# NUC100DN_v1 register map
File version: 1.0
Registers are 32-bit, read-write, reset 0x0 unless marked. A register's access mark holds for its fields unless they carry their own. Offsets are from the block's base; [hi:lo] are bit positions; {n}, {i} and the like mark numbered series.

## GCR — GCR Register Map
Base 0x50000000
0x00 PDID ro reset 0x20140018 — Part Device Identification Number Register
  [31:0] PDID — Part Device Identification Number. This register reflects device part number code. Software can read this register to identify which device is used.
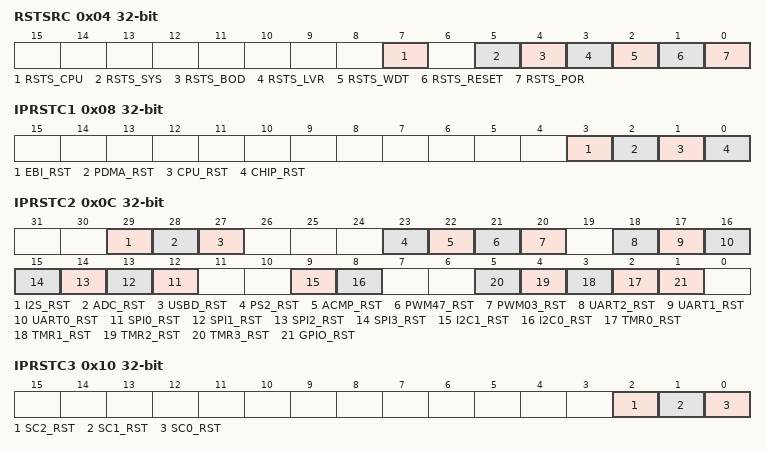
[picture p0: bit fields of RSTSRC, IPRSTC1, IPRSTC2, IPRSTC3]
0x04 RSTSRC (reset mask 0xFFFFFF00) — System Reset Source Register
  [7] RSTS_CPU — CPU Reset Flag. The RSTS_CPU flag is set by hardware if software writes cpu_rst (iprstc1[1]) 1 to reset Cortex-M0 cpu core and flash memory controller (fmc). Note: This bit can be cleared by writing '1' to it.
    0=No reset from CPU; 1=Cortex-M0 CPU core and FMC are reset by software setting CPU_RST to 1
  [5] RSTS_SYS — SYS Reset Flag. The RSTS_SYS flag is set by the "reset signal" from the Cortex-M0 core to indicate the previous reset source. Note: This bit can be cleared by writing '1' to it.
    0=No reset from Cortex-M0; 1=The Cortex-M0 had issued the reset signal to reset the system by writing 1 to bit SYSRESETREQ (AIRCR[2], Application Interrupt and Reset Control Register, address = 0xE000ED0C) in system control registers of Cortex-M0 core
  [4] RSTS_BOD — Brown-out Detector Reset Flag. The RSTS_BOD flag is set by the "reset signal" from the brown-out detector to indicate the previous reset source. Note: This bit can be cleared by writing '1' to it.
    0=No reset from BOD; 1=The BOD had issued the reset signal to reset the system
  [3] RSTS_LVR — Low Voltage Reset Flag. The RSTS_LVR flag is set by the "reset signal" from fhe low-voltage-reset controller fo indicate the previous reset source. Note: This bit can be cleared by writing '1' to it.
    0=No reset from LVR; 1=The LVR controller had issued the reset signal to reset the system
  [2] RSTS_WDT — Watchdog Timer Reset Flag. The RSTS_WDT flag is set by the "reset signal" from the watchdog timer to indicate the previous reset source. Note: This bit can be cleared by writing '1' to it.
    0=No reset from watchdog timer; 1=The watchdog timer had issued the reset signal to reset the system
  [1] RSTS_RESET — Reset Pin Reset Flag. The RSTS_RESET flag is set by the "reset signal" from the /reset pin to indicate the previous reset source. Note: This bit can be cleared by writing '1' to it.
    0=No reset from /RESET pin; 1=The Pin /RESET had issued the reset signal to reset the system
  [0] RSTS_POR — Power-on Reset Flag. The RSTS_POR flag is Set by the "Reset Signal" from the Power-on Reset (POR) controller or the bit CHIP_RST (IPRSTC1[0]) to indicate the previous reset source. Note: This bit can be cleared by writing '1' to it.
    0=No reset from POR or CHIP_RST; 1=Power-on Reset (POR) or CHIP_RST had issued the reset signal to reset the system
0x08 IPRSTC1 — IP Reset Control Register 1
  [3] EBI_RST — EBI Controller Reset (Write Protect). Set this bit to 1 will generate a reset signal to the EBI. User need to set this bit to 0 to release from the reset state. This bit is the protected bit, It means programming this bit needs to write "59h", "16h", "88h" to address 0x5000_0100 to disable register protection. Refer to the register REGWRPROT at address GCR_BA+0x100
    0=EBI controller normal operation; 1=EBI controller reset
  [2] PDMA_RST — PDMA Controller Reset (Write Protect). Setting this bit to 1 will generate a reset signal to the PDMA. User need to set this bit to 0 to release from reset state. This bit is the protected bit, It means programming this bit needs to write "59h", "16h", "88h" to address 0x5000_0100 to disable register protection. Refer to the register REGWRPROT at address GCR_BA+0x100.
    0=PDMA controller normal operation; 1=PDMA controller reset
  [1] CPU_RST — CPU Core One-shot Reset (Write Protect). Setting this bit will only reset the CPU core and Flash Memory Controller(FMC), and this bit will automatically return 0 after the two clock cycles. This bit is the protected bit, It means programming this bit needs to write "59h", "16h", "88h" to address 0x5000_0100 to disable register protection. Refer to the register REGWRPROT at address GCR_BA+0x100
    0=CPU normal operation; 1=CPU one-shot reset
  [0] CHIP_RST — CHIP One-shot Reset (Write Protect). Setting this bit will reset the whole chip, including CPU core and all peripherals, and this bit will automatically return to 0 after the 2 clock cycles. The CHIP_RST is the same as the POR reset, all the chip controllers are reset and the chip setting from flash are also reload. For the difference between CHIP_RST and SYSRESETREQ, please refer to section 5.2.2. This bit is the protected bit. It means programming this bit needs to write "59h", "16h", "88h" to address 0x5000_0100 to disable register protection. Refer to the register REGWRPROT at address GCR_BA+0x100
    0=CHIP normal operation; 1=CHIP one-shot reset
0x0C IPRSTC2 — IP Reset Control Register 2
  [29] I2S_RST — I2S Controller Reset
    0=I2S controller normal operation; 1=I2S controller reset
  [28] ADC_RST — ADC Controller Reset
    0=ADC controller normal operation; 1=ADC controller reset
  [27] USBD_RST — USB Device Controller Reset
    0=USB device controller normal operation; 1=USB device controller reset
  [23] PS2_RST — PS/2 Controller Reset
    0=PS/2 controller normal operation; 1=PS/2 controller reset
  [22] ACMP_RST — Analog Comparator Controller Reset
    0=Analog Comparator controller normal operation; 1=Analog Comparator controller reset
  [21] PWM47_RST — PWM47 Controller Reset
    0=PWM47 controller normal operation; 1=PWM47 controller reset
  [20] PWM03_RST — PWM03 Controller Reset
    0=PWM03 controller normal operation; 1=PWM03 controller reset
  [18] UART2_RST — UART2 Controller Reset
    0=UART2 controller normal operation; 1=UART2 controller reset
  [17] UART1_RST — UART1 Controller Reset
    0=UART1 controller normal operation; 1=UART1 controller reset
  [16] UART0_RST — UART0 Controller Reset
    0=UART0 controller normal operation; 1=UART0 controller reset
  [n+12] SPI{n}_RST (n=0..3) — SPI{n} Controller Reset
    0=SPI{n} controller normal operation; 1=SPI{n} controller reset
  [9] I2C1_RST — I2C1 Controller Reset
    0=I2C1 controller normal operation; 1=I2C1 controller reset
  [8] I2C0_RST — I2C0 Controller Reset
    0=I2C0 controller normal operation; 1=I2C0 controller reset
  [n+2] TMR{n}_RST (n=0..3) — Timer{n} Controller Reset
    0=Timer{n} controller normal operation; 1=Timer{n} controller reset
  [1] GPIO_RST — GPIO Controller Reset
    0=GPIO controller normal operation; 1=GPIO controller reset
0x10 IPRSTC3 — IP Reset Control Register 3
  [2] SC2_RST — SC2 Controller Reset
    0=SC2 controller normal operation; 1=SC2 controller reset
  [1] SC1_RST — SC1 Controller Reset
    0=SC1 controller normal operation; 1=SC1 controller reset
  [0] SC0_RST — SC0 Controller Reset
    0=SC0 controller normal operation; 1=SC0 controller reset
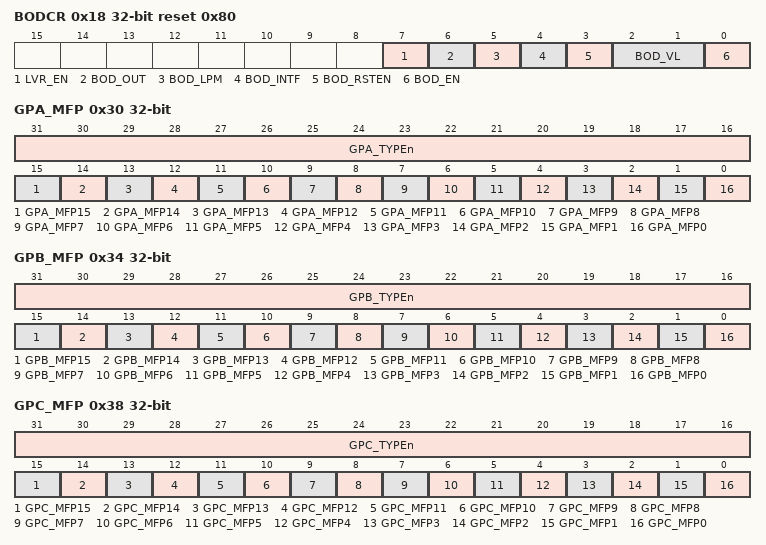
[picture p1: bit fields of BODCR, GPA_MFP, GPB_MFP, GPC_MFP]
0x18 BODCR reset 0x80 (reset mask 0xFFFFFFF0) — Brown-out Detector Control Register
  [7] LVR_EN — Low Voltage Reset Enable Bit (Write Protect). The LVR function reset the chip when the input power voltage is lower than LVR circuit setting. LVR function is enabled by default. This bit is the protected bit. It means programming this needs to write "59h", "16h", "88h" to address 0x5000_0100 to disable register protection. Refer to the register REGWRPROT at address GCR_BA+0x100
    0=Low Voltage Reset function Disabled; 1=Low Voltage Reset function Enabled - After enabling the bit, the LVR function will be active with 100us delay for LVR output stable (default)
  [6] BOD_OUT — Brown-out Detector Output Status
    0=Brown-out Detector output status is 0. It means the detected voltage is higher than BOD_VL setting or BOD_EN is 0; 1=Brown-out Detector output status is 1. It means the detected voltage is lower than BOD_VL setting. If the BOD_EN is 0, BOD function disabled , this bit always responds to 0
  [5] BOD_LPM — Brown-out Detector Low Power Mode (Write Protect). The BOD consumes about 100 uA in Normal mode, and the low power mode can reduce the current to about 1/10 but slow the BOD response. This bit is the protected bit which means programming this needs to write "59h", "16h", "88h" to address 0x5000_0100 to disable register protection. Refer to the register REGWRPROT at address GCR_BA+0x100.
    0=BOD operated in Normal mode (default); 1=BOD Low Power mode Enabled
  [4] BOD_INTF — Brown-out Detector Interrupt Flag. Note: This bit can be cleared by writing '1' to it.
    0=Brown-out Detector does not detect any voltage draft at VDD down through or up through the voltage of BOD_VL setting; 1=When Brown-out Detector detects the VDD is dropped down through the voltage of BOD_VL setting or the VDD is raised up through the voltage of BOD_VL setting, this bit is set to 1 and the Brown-out interrupt is requested if Brown-out interrupt is enabled
  [3] BOD_RSTEN — Brown-out Reset Enable Bit (Write Protect). While the Brown-out Detector function is enabled (BOD_EN high) and BOD reset function is enabled (BOD_RSTEN high), BOD will assert a signal to reset chip when the detected voltage is lower than the threshold (BOD_OUT high). The default value is set by flash controller user configuration register config0 bit[20]. This bit is the protected bit. It means programming this needs to write "59h", "16h", "88h" to address 0x5000_0100 to disable register protection. Refer to the register REGWRPROT at address GCR_BA+0x100.
    0=Brown-out "INTERRUPT" function Enabled; 1=Brown-out "RESET" function Enabled
  [2:1] BOD_VL — Brown-out Detector Threshold Voltage Selection (Write Protect)
  [0] BOD_EN — Brown-out Detector Enable Bit (Write Protect). The default value is set by flash controller user configuration register config0 bit[23]. This bit is the protected bit which means programming this needs to write "59h", "16h", "88h" to address 0x5000_0100 to disable register protection. Refer to the register REGWRPROT at address GCR_BA+0x100.
    0=Brown-out Detector function Disabled; 1=Brown-out Detector function Enabled
0x1C TEMPCR — Temperature Sensor Control Register
  [0] VTEMP_EN — Temperature Sensor Enable Bit. This bit is used to enable/disable temperature sensor function. After this bit is set to 1, the value of temperature can be obtained from ADC conversion result by ADC channel selecting channel 7 and alternative multiplexer channel selecting temperature sensor. Please refer to the ADC function chapter for detail ADC conversion functional description.
    0=Temperature sensor function Disabled (default); 1=Temperature sensor function Enabled
0x24 PORCR (reset mask 0xFFFFFF00) — Power-on-reset Controller Register
  [15:0] POR_DIS_CODE — Power-on-reset Enable Control (Write Protect). When powered on, the POR circuit generates a reset signal to reset the whole chip function, but noise on the power may cause the POR active again. User can disable internal POR circuit to avoid unpredictable noise to cause chip reset by writing 0x5AA5 to this field. The POR function will be active again when this field is set to another value or chip is reset by other reset source, including: /RESET, Watchdog, LVR reset, BOD reset, ICE reset command and the software-chip reset function. This bit is the protected bit which means programming this needs to write "59h", "16h", "88h" to address 0x5000_0100 to disable register protection. Refer to the register REGWRPROT at address GCR_BA+0x100.
0x30 GPA_MFP — GPIOA Multiple Function and Input Type Control Register
  [31:16] GPA_TYPEn — Input Schmitt Trigger Enable Bit
    0=GPIOA[15:0] I/O input Schmitt Trigger function Disabled; 1=GPIOA[15:0] I/O input Schmitt Trigger function Enabled
  [15] GPA_MFP15 — PA.15 Pin Function Selection
  [14] GPA_MFP14 — PA.14 Pin Function Selection
  [13] GPA_MFP13 — PA.13 Pin Function Selection
  [12] GPA_MFP12 — PA.12 Pin Function Selection
  [11] GPA_MFP11 — PA.11 Pin Function Selection
  [10] GPA_MFP10 — PA.10 Pin Function Selection
  [9] GPA_MFP9 — PA.9 Pin Function Selection
    0=GPIOA[9] selected to the pin PA.9; 1=I2C0 SCL function selected to the pin PA.9
  [8] GPA_MFP8 — PA.8 Pin Function Selection
    0=GPIOA[8] selected to the pin PA.8; 1=I2C0 SDA function selected to the pin PA.8
  [7] GPA_MFP7 — PA.7 Pin Function Selection
  [6] GPA_MFP6 — PA.6 Pin Function Selection
  [5] GPA_MFP5 — PA.5 Pin Function Selection
  [4] GPA_MFP4 — PA.4 Pin Function Selection
  [3] GPA_MFP3 — PA.3 Pin Function Selection
  [2] GPA_MFP2 — PA.2 Pin Function Selection
  [1] GPA_MFP1 — PA.1 Pin Function Selection
  [0] GPA_MFP0 — PA.0 Pin Function Selection
0x34 GPB_MFP — GPIOB Multiple Function and Input Type Control Register
  [31:16] GPB_TYPEn — Input Schmitt Trigger Enable Bit
    0=GPIOB[15:0] I/O input Schmitt Trigger function Disabled; 1=GPIOB[15:0] I/O input Schmitt Trigger function Enabled
  [15] GPB_MFP15 — PB.15 Pin Function Selection
  [14] GPB_MFP14 — PB.14 Pin Function Selection
  [13] GPB_MFP13 — PB.13 Pin Function Selection
  [12] GPB_MFP12 — PB.12 Pin Function Selection
  [11] GPB_MFP11 — PB.11 Pin Function Selection
  [10] GPB_MFP10 — PB.10 Pin Function Selection
  [9] GPB_MFP9 — PB.9 Pin Function Selection
  [8] GPB_MFP8 — PB.8 Pin Function Selection
    0=GPIOB[8] selected to the pin PB.8; 1=TM0 (Timer/Counter external trigger clock input) function selected to the pin PB.8
  [7] GPB_MFP7 — PB.7 Pin Function Selection
  [6] GPB_MFP6 — PB.6 Pin Function Selection
  [5] GPB_MFP5 — PB 5 Pin Function Selection
    0=GPIOB[5] is selected to the pin PB.5; 1=UART1 TXD function is selected to the pin PB.5
  [4] GPB_MFP4 — PB.4 Pin Function Selection
    0=GPIOB[4] is selected to the pin PB.4; 1=UART1 RXD function is selected to the pin PB.4
  [3] GPB_MFP3 — PB.3 Pin Function Selection
  [2] GPB_MFP2 — PB.2 Pin Function Selection
  [1] GPB_MFP1 — PB.1 Pin Function Selection
    0=GPIOB[1] is selected to the pin PB.1; 1=UART0 TXD function is selected to the pin PB.1
  [0] GPB_MFP0 — PB.0 Pin Function Selection
    0=GPIOB[0] is selected to the pin PB.0; 1=UART0 RXD function is selected to the pin PB.0
0x38 GPC_MFP — GPIOC Multiple Function and Input Type Control Register
  [31:16] GPC_TYPEn — Input Schmitt Trigger Enable Bit
    0=GPIOC[15:0] I/O input Schmitt Trigger function Disabled; 1=GPIOC[15:0] I/O input Schmitt Trigger function Enabled
  [15] GPC_MFP15 — PC.15 Pin Function Selection
  [14] GPC_MFP14 — PC.14 Pin Function Selection
  [13] GPC_MFP13 — PC.13 Pin Function Selection
    0=GPIOC[13] is selected to the pin PC.13; 1=SPI1 MOSI1 (master output, slave input pin-1) function is selected to the pin PC.13
  [12] GPC_MFP12 — PC.12 Pin Function Selection
    0=GPIOC[12] is selected to the pin PC.12; 1=SPI1 MISO1 (master input, slave output pin-1) function is selected to the pin PC.12
  [11] GPC_MFP11 — PC.11 Pin Function Selection
    0=GPIOC[11] selected to the pin PC.11; 1=SPI1 MOSI0 (master output, slave input pin-0) function selected to the pin PC.11
  [10] GPC_MFP10 — PC.10 Pin Function Selection
    0=GPIOC[10] is selected to the pin PC.10; 1=SPI1 MISO0 (master input, slave output pin-0) function selected to the pin PC.10
  [9] GPC_MFP9 — PC.9 Pin Function Selection
    0=GPIOC[9] selected to the pin PC.9; 1=SPI1 SPICLK function selected to the pin PC.9
  [8] GPC_MFP8 — PC.8 Pin Function Selection
  [7] GPC_MFP7 — PC.7 Pin Function Selection
  [6] GPC_MFP6 — PC.6 Pin Function Selection
  [5] GPC_MFP5 — PC.5 Pin Function Selection
    0=GPIOC[5] is selected to the pin PC.5; 1=SPI0 MOSI1 (master output, slave input pin-1) function is selected to the pin PC.5
  [4] GPC_MFP4 — PC.4 Pin Function Selection
    0=GPIOC[4] is selected to the pin PC.4; 1=SPI0 MISO1 (master input, slave output pin-1) function is selected to the pin PC.4
  [3] GPC_MFP3 — PC.3 Pin Function Selection
  [2] GPC_MFP2 — PC.2 Pin Function Selection
  [1] GPC_MFP1 — PC.1 Pin Function Selection
  [0] GPC_MFP0 — PC.0 Pin Function Selection
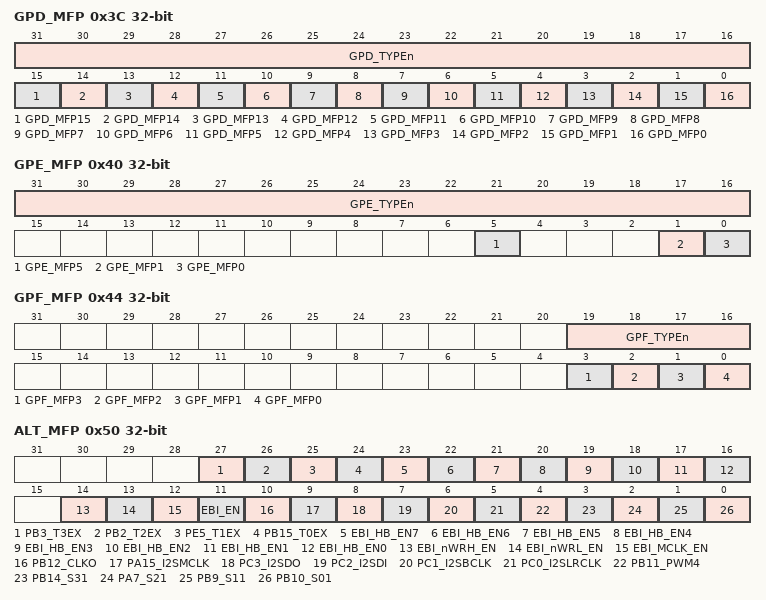
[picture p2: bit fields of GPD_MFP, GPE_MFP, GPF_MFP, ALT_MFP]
0x3C GPD_MFP — GPIOD Multiple Function and Input Type Control Register
  [31:16] GPD_TYPEn — Input Schmitt Trigger Enable Bit
    0=GPIOD[15:0] I/O input Schmitt Trigger function Disabled; 1=GPIOD[15:0] I/O input Schmitt Trigger function Enabled
  [15] GPD_MFP15 — PD.15 Pin Function Selection
    0=GPIOD[15] selected to the pin PD.15; 1=UART2 TXD function is selected to the pin PD.15
  [14] GPD_MFP14 — PD.14 Pin Function Selection
    0=GPIOD[14] selected to the pin PD.14; 1=UART2 RXD function is selected to the pin PD.14
  [13] GPD_MFP13 — PD.13 Pin Function Selection
    0=GPIOD[13] is selected to the pin PD.13; 1=SPI3 MOSI1 (master output, slave input pin-1) function is selected to the pin PD.13
  [12] GPD_MFP12 — PD.12 Pin Function Selection
    0=GPIOD[12] is selected to the pin PD.12; 1=SPI3 MISO1 (master input, slave output pin-1) function is selected to the pin PD.12
  [11] GPD_MFP11 — PD.11 Pin Function Selection
    0=GPIOD[11] is selected to the pin PD.11; 1=SPI3 MOSI0 (master output, slave input pin-0) function is selected to the pin PD.11
  [10] GPD_MFP10 — PD.10 Pin Function Selection
    0=GPIOD[10] is selected to the pin PD.10; 1=SPI3 MISO0 (master input, slave output pin-0) function is selected to the pin PD.10
  [9] GPD_MFP9 — PD.9 Pin Function Selection
    0=GPIOD[9] is selected to the pin PD.9; 1=SPI3 SPICLK function is selected to the pin PD.9
  [8] GPD_MFP8 — PD.8 Pin Function Selection
    0=GPIOD[8] is selected to the pin PD8; 1=SPI3 SS30 function is selected to the pin PD8
  [7] GPD_MFP7 — Reserved.
  [6] GPD_MFP6 — Reserved.
  [5] GPD_MFP5 — PD.5 Pin Function Selection
    0=GPIOD[5] is selected to the pin PD.5; 1=SPI2 MOSI1 (master output, slave input pin-1) function is selected to the pin PD.5
  [4] GPD_MFP4 — PD.4 Pin Function Selection
    0=GPIOD[4]is selected to the pin PD.4; 1=SPI2 MISO1 (master input, slave output pin-1) function is selected to the pin PD.4
  [3] GPD_MFP3 — PD.3 Pin Function Selection
    0=GPIOD[3] selected to the pin PD.3; 1=SPI2 MOSI0 (master output, slave input pin-0) function selected to the pin PD.3
  [2] GPD_MFP2 — PD.2 Pin Function Selection
    0=GPIOD[2] selected to the pin PD.2; 1=SPI2 MISO0 (master input, slave output pin-0) function selected to the pin PD.2
  [1] GPD_MFP1 — PD.1 Pin Function Selection
    0=GPIOD[1] selected to the pin PD.1; 1=SPI2 SPICLK function selected to the pin PD.1
  [0] GPD_MFP0 — PD.0 Pin Function Selection
    0=GPIOD[0] selected to the pin PD.0; 1=SPI2 SS20 function selected to the pin PD.0
0x40 GPE_MFP — GPIOE Multiple Function and Input Type Control Register
  [31:16] GPE_TYPEn — Input Schmitt Trigger Enable Bit
    0=GPIOE[15:0] I/O input Schmitt Trigger function Disabled; 1=GPIOE[15:0] I/O input Schmitt Trigger function Enabled
  [5] GPE_MFP5 — PE.5 Pin Function Selection
  [1] GPE_MFP1 — PE.1 Pin Function Selection
    0=GPIOE[1] is selected to the pin PE.1; 1=PWM7 function is selected to the pin PE.1
  [0] GPE_MFP0 — PE.0 Pin Function Selection
    0=GPIOE[0] is selected to the pin PE.0; 1=PWM6 function is selected to the pin PE.0
0x44 GPF_MFP (reset mask 0xFFFFFFF0) — GPIOF Multiple Function and Input Type Control Register
  [19:16] GPF_TYPEn — Input Schmitt Trigger Enable Bit
    0=GPIOF[3:0] I/O input Schmitt Trigger function Disabled; 1=GPIOF[3:0] I/O input Schmitt Trigger function Enabled
  [3] GPF_MFP3 — PF.3 Pin Function Selection
    0=GPIOF[3] is selected to the pin PF.3; 1=PS2CLK function is selected to the pin PF.3
  [2] GPF_MFP2 — PF.2 Pin Function Selection
    0=GPIOF[2] is selected to the pin PF.2; 1=PS2DAT function is selected to the pin PF.2
  [1] GPF_MFP1 — PF.1 Pin Function Selection. Note: This bit is read only and is decided by user configuration CGPFMFP (Config0[27]).
    0=GPIOF[1] is selected to the pin PF.1; 1=XT1_IN function is selected to the pin PF.1
  [0] GPF_MFP0 — PF.0 Pin Function Selection. Note: This bit is read only and is decided by user configuration CGPFMFP (Config0[27]).
    0=GPIOF[0] is selected to the pin PF.0; 1=XT1_OUT function is selected to the pin PF.0
0x50 ALT_MFP — Alternative Multiple Function Pin Control Register
  [27] PB3_T3EX — PB.3 Pin Function Selection
  [26] PB2_T2EX — PB.2 Pin Function Selection
  [25] PE5_T1EX — PE.5 Pin Function Selection
  [24] PB15_T0EX — PB.15 Pin Function Selection
  [23] EBI_HB_EN7 — PA.14 Pin Function Selection
  [22] EBI_HB_EN6 — PA.13 Pin Function Selection
  [21] EBI_HB_EN5 — PA.12 Pin Function Selection
  [20] EBI_HB_EN4 — PA.1 Pin Function Selection
  [19] EBI_HB_EN3 — PA.2 Pin Function Selection
  [18] EBI_HB_EN2 — PA.3 Pin Function Selection
  [17] EBI_HB_EN1 — PA.4 Pin Function Selection
  [16] EBI_HB_EN0 — PA.5 Pin Function Selection
  [14] EBI_nWRH_EN — PB.3 Pin Function Selection
  [13] EBI_nWRL_EN — PB.2 Pin Function Selection
  [12] EBI_MCLK_EN — PC.8 Pin Function Selection
  [11] EBI_EN — EBI Function Selection
  [10] PB12_CLKO — PB.12 Pin Function Selection
  [9] PA15_I2SMCLK — PA.15 Pin Function Selection
  [8] PC3_I2SDO — PC.3 Pin Function Selection
  [7] PC2_I2SDI — PC.2 Pin Function Selection
  [6] PC1_I2SBCLK — PC.1 Pin Function Selection
  [5] PC0_I2SLRCLK — PC.0 Pin Function Selection
  [4] PB11_PWM4 — PB.11 Pin Function Selection
  [3] PB14_S31 — PB.14 Pin Function Selection
  [2] PA7_S21 — PA.7 Pin Function Selection
  [1] PB9_S11 — PB.9 Pin Function Selection
  [0] PB10_S01 — PB.10 Pin Function Selection
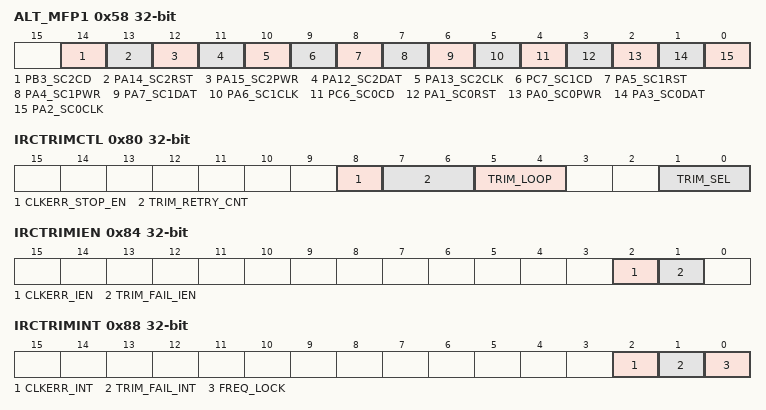
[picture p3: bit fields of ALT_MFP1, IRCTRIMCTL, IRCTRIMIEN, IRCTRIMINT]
0x58 ALT_MFP1 — Alternative Multiple Function Pin Control Register 1
  [14] PB3_SC2CD — PB.3 Pin Function Selection
  [13] PA14_SC2RST — PA.14 Pin Function Selection
  [12] PA15_SC2PWR — PA.15 Pin Function Selection
  [11] PA12_SC2DAT — PA.12 Pin Function Selection
  [10] PA13_SC2CLK — PA.13 Pin Function Selection
  [9] PC7_SC1CD — PC.7 Pin Function Selection
  [8] PA5_SC1RST — PA.5 Pin Function Selection
  [7] PA4_SC1PWR — PA.4 Pin Function Selection
  [6] PA7_SC1DAT — PA.7 Pin Function Selection
  [5] PA6_SC1CLK — PA.6 Pin Function Selection
  [4] PC6_SC0CD — PC.6 Pin Function Selection
  [3] PA1_SC0RST — PA.1 Pin Function Selection
  [2] PA0_SC0PWR — PA.0 Pin Function Selection
  [1] PA3_SC0DAT — PA.3 Pin Function Selection
  [0] PA2_SC0CLK — PA.2 Pin Function Selection
0x80 IRCTRIMCTL — IRC Trim Control Register
  [8] CLKERR_STOP_EN — Clock Error Stop Enable Bit. When this bit is set to 1, the trim operation is stopped if clock is inaccuracy. When this bit is set to 0, the trim operation is keep going if clock is inaccuracy.
  [7:6] TRIM_RETRY_CNT — Trim Value Update Limitation Count. The field defines that how many times of HIRC trim value is updated by auto trim circuit before the HIRC frequency locked. Once the HIRC locked, the internal trim value update counter will be reset. If the trim value update counter reached this limitation value and frequency of HIRC still doesn't lock, the auto trim operation will be disabled and TRIM_SEL will be cleared to 00.
    0=Trim retry count limitation is 64; 1=Trim retry count limitation is 128; 2=Trim retry count limitation is 256; 3=Trim retry count limitation is 512
  [5:4] TRIM_LOOP — Trim Calculation Loop. This field defines that trim value calculation is based on how many 32.768 kHz clocks in. For example, if TRIM_LOOP is set as 00, auto trim circuit will calculate trim value based on the average frequency difference in 4 32.768 kHz clock.
    0=Trim value calculation is based on average difference in 4 clocks; 1=Trim value calculation is based on average difference in 8 clocks; 2=Trim value calculation is based on average difference in 16 clocks; 3=Trim value calculation is based on average difference in 32 clocks
  [1:0] TRIM_SEL — Trim Frequency Selection. This field indicates the target frequency of internal 22.1184 MHz high speed oscillator will trim to precise 22.1184MHz or 24MHz automatically. If no any target frequency is selected (TRIM_SEL is 00), the HIRC auto trim function is disabled. During auto trim operation, if clock error detected because of CLKERR_STOP_EN is set to 1 or trim retry limitation counts reached, this field will be cleared to 00 automatically.
    0=HIRC auto trim function Disabled; 1=HIRC auto trim function Enabled and HIRC trimmed to 22.1184 MHz; 2=HIRC auto trim function Enabled and HIRC trimmed to 24 MHz
0x84 IRCTRIMIEN — IRC Trim Interrupt Enable Register
  [2] CLKERR_IEN — Clock Error Interrupt Enable Bit. This bit controls if CPU would get an interrupt while clock is inaccuracy during auto trim operation. If this bit is set to1, and CLKERR_INT is set during auto trim operation. An interrupt will be triggered to notify the clock frequency is inaccuracy.
    0=CLKERR_INT status to trigger an interrupt to CPU Disabled; 1=CLKERR_INT status to trigger an interrupt to CPU Enabled
  [1] TRIM_FAIL_IEN — Trim Failure Interrupt Enable Bit. This bit controls if an interrupt will be triggered while HIRC trim value update limitation count reached and HIRC frequency still not locked on target frequency set by TRIM_SEL. If this bit is high and TRIM_FAIL_INT is set during auto trim operation. An interrupt will be triggered to notify that HIRC trim value update limitation count was reached.
    0=TRIM_FAIL_INT status to trigger an interrupt to CPU Disabled; 1=TRIM_FAIL_INT status to trigger an interrupt to CPU Enabled
0x88 IRCTRIMINT — IRC Trim Interrupt Status Register
  [2] CLKERR_INT — Clock Error Interrupt Status. When the frequency of external 32.768 kHz low speed crystal or internal 22.1184 MHz high speed oscillator is shift larger to unreasonable value, this bit will be set and to be an indicate that clock frequency is inaccuracy. Once this bit is set to 1, the auto trim operation stopped and TRIM_SEL will be cleared to 00 by hardware automatically if CLKERR_STOP_EN is set to 1. If this bit is set and CLKERR_IEN is high, an interrupt will be triggered to notify the clock frequency is inaccuracy. Write 1 to clear this to 0.
    0=Clock frequency is accurate; 1=Clock frequency is inaccurate
  [1] TRIM_FAIL_INT — Trim Failure Interrupt Status. This bit indicates that internal 22.1184 MHz high speed oscillator trim value update limitation count reached and the internal 22.1184 MHz high speed oscillator clock frequency still doesn't be locked. Once this bit is set, the auto trim operation stopped and TRIM_SEL will be cleared to 00 by hardware automatically. If this bit is set and TRIM_FAIL_IEN is high, an interrupt will be triggered to notify that HIRC trim value update limitation count was reached. Write 1 to clear this to 0.
    0=Trim value update limitation count did not reach; 1=Trim value update limitation count reached and internal 22.1184 MHz high speed oscillator frequency was still not locked
  [0] FREQ_LOCK — HIRC Frequency Lock Status. This bit indicates the internal 22.1184 MHz high speed oscillator frequency is locked. This is a status bit and doesn't trigger any interrupt.
0x100 REGWRPROT — Register Write Protection Register
  [7:0] REGWRPROT — Register Write-protection Code. Some registers have write-protection function. Writing these registers have to disable the protected function by writing the sequence value "59h", "16h", "88h" to this field. After this sequence is completed, the REGPROTDIS bit will be set to 1 and write-protection registers can be normal write. Register Write-protection Disable Index
    0=Write-protection is enabled for writing protected registers. Any write to the protected register is ignored; 1=Write-protection is disabled for writing protected registers
